AUTOSAR XML (schema 4-2-2)
package /ComponentTypes
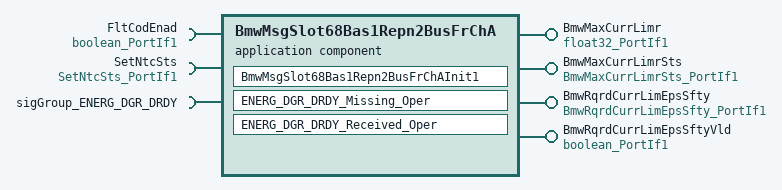
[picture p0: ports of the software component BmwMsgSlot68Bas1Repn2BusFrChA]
  application sw component type BmwMsgSlot68Bas1Repn2BusFrChA
    4 x provide port:
      BmwMaxCurrLimr: nonqueued-sender-com-spec=data-element=Val, provided-interface=float32_PortIf1
      BmwMaxCurrLimrSts: nonqueued-sender-com-spec{data-element=Val, init-value=4}, provided-interface=BmwMaxCurrLimrSts_PortIf1
      BmwRqrdCurrLimEpsSfty: nonqueued-sender-com-spec{data-element=Val, init-value=15}, provided-interface=BmwRqrdCurrLimEpsSfty_PortIf1
      BmwRqrdCurrLimEpsSftyVld: nonqueued-sender-com-spec{data-element=Logl, init-value=1}, provided-interface=boolean_PortIf1
    require port FltCodEnad: nonqueued-receiver-com-spec{data-element=Logl, filter=data-filter-type=ALWAYS, init-value=1}, required-interface=boolean_PortIf1
    require port SetNtcSts: client-com-spec=Oper, required-interface=SetNtcSts_PortIf1
    require port sigGroup_ENERG_DGR_DRDY: nonqueued-receiver-com-spec{data-element=sigGroup_ENERG_DGR_DRDY, uses-end-to-end-protection=true, alive-timeout=0.015, enable-update=true, filter=data-filter-type=ALWAYS, init-value=fields=[MAX_I_LD_SPEC_ARS:0, MAX_I_RECUP_SPEC_ARS:0, RQ_CULI_EST_SFY:15, ALIV_ENERG_DGR_DRDY:15, ENERG_AVAI_ARS:0, QU_DGR_AISP_ENERG:0, CRC_ENERG_DGR_DRDY:0, MAX_I_SPEC_BAX_STE:0, ENERG_DGR_DRDY_dummy_12_15:0, MAX_I_SPEC_EPS:255]}, required-interface=sigGroup_ENERG_DGR_DRDY
    behavior BmwMsgSlot68Bas1Repn2BusFrChA_InternalBehavior
      ar-typed-per-instance-memorys:
        12 x data, all with sw-calibration-access=READ-ONLY:
          AlvFaildCnt: type=uint8
          AlvPassdCnt: type=uint8
          BmwMaxCurrLimrPrev: type=float32
          BmwRqrdCurrLimEpsSftyPrev: type=uint8
          CrcFaildCnt: type=uint8
          CrcPassdCnt: type=uint8
          MaxCurrSpecEPSFaildCnt: type=uint8
          MaxCurrSpecEPSPassdCnt: type=uint8
          MissingMsgCnt: type=uint8
          RqCuliEstSfyFaildCnt: type=uint8
          RqCuliEstSfyPassdCnt: type=uint8
          RxdMsgCnt: type=uint8
      init event BmwMsgSlot68Bas1Repn2BusFrChA_InitEvent: start-on-event=BmwMsgSlot68Bas1Repn2BusFrChAInit1
      data receive error event DRET_ENERG_DGR_DRDY_Missing_Oper_sigGroup_ENERG_DGR_DRDY_sigGroup_ENERG_DGR_DRDY: start-on-event=ENERG_DGR_DRDY_Missing_Oper, data=sigGroup_ENERG_DGR_DRDY.sigGroup_ENERG_DGR_DRDY
      data received event DRT_ENERG_DGR_DRDY_Received_Oper_sigGroup_ENERG_DGR_DRDY_sigGroup_ENERG_DGR_DRDY: start-on-event=ENERG_DGR_DRDY_Received_Oper, data=sigGroup_ENERG_DGR_DRDY.sigGroup_ENERG_DGR_DRDY
      port-api-options:
        enable-take-address=false, error-handling=NO-TRANSFORMER-ERROR-HANDLING, indirect-api=false, port=BmwMaxCurrLimr
        enable-take-address=false, error-handling=NO-TRANSFORMER-ERROR-HANDLING, indirect-api=false, port=BmwMaxCurrLimrSts
        enable-take-address=false, error-handling=NO-TRANSFORMER-ERROR-HANDLING, indirect-api=false, port=BmwRqrdCurrLimEpsSfty
        enable-take-address=false, error-handling=NO-TRANSFORMER-ERROR-HANDLING, indirect-api=false, port=BmwRqrdCurrLimEpsSftyVld
        enable-take-address=false, error-handling=NO-TRANSFORMER-ERROR-HANDLING, indirect-api=false, port=FltCodEnad
        enable-take-address=false, error-handling=NO-TRANSFORMER-ERROR-HANDLING, indirect-api=false, port=SetNtcSts
        enable-take-address=false, error-handling=NO-TRANSFORMER-ERROR-HANDLING, indirect-api=false, port=sigGroup_ENERG_DGR_DRDY
      runnable BmwMsgSlot68Bas1Repn2BusFrChAInit1
        sync call SC_SetNtcSts_Oper: operation=SetNtcSts.Oper, timeout=0
      runnable ENERG_DGR_DRDY_Missing_Oper
        data-receive-point-by-arguments:
          access REC_FltCodEnad_Logl: accessed-variable=FltCodEnad.Logl
        data-send-points:
          4 x access:
            SEND_BmwMaxCurrLimr_Val: accessed-variable=BmwMaxCurrLimr.Val
            SEND_BmwMaxCurrLimrSts_Val: accessed-variable=BmwMaxCurrLimrSts.Val
            SEND_BmwRqrdCurrLimEpsSfty_Val: accessed-variable=BmwRqrdCurrLimEpsSfty.Val
            SEND_BmwRqrdCurrLimEpsSftyVld_Logl: accessed-variable=BmwRqrdCurrLimEpsSftyVld.Logl
        sync call SC_SetNtcSts_Oper: operation=SetNtcSts.Oper, timeout=0
      runnable ENERG_DGR_DRDY_Received_Oper
        data-receive-point-by-arguments:
          access REC_FltCodEnad_Logl: accessed-variable=FltCodEnad.Logl
          access REC_sigGroup_ENERG_DGR_DRDY_sigGroup_ENERG_DGR_DRDY: accessed-variable=sigGroup_ENERG_DGR_DRDY.sigGroup_ENERG_DGR_DRDY
        data-send-points:
          4 x access:
            SEND_BmwMaxCurrLimr_Val: accessed-variable=BmwMaxCurrLimr.Val
            SEND_BmwMaxCurrLimrSts_Val: accessed-variable=BmwMaxCurrLimrSts.Val
            SEND_BmwRqrdCurrLimEpsSfty_Val: accessed-variable=BmwRqrdCurrLimEpsSfty.Val
            SEND_BmwRqrdCurrLimEpsSftyVld_Logl: accessed-variable=BmwRqrdCurrLimEpsSftyVld.Logl
        sync call SC_SetNtcSts_Oper: operation=SetNtcSts.Oper, timeout=0
  swc implementation BmwMsgSlot68Bas1Repn2BusFrChA_Implementation: behavior=BmwMsgSlot68Bas1Repn2BusFrChA_InternalBehavior
    code-descriptors:
      code Default: artifact-descriptors=autosar-engineering-object={short-label=Default, category=SWSRC}
